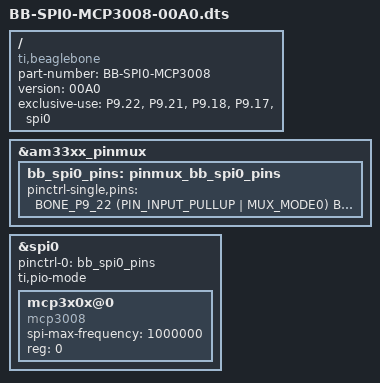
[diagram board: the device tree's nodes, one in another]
/*
 * Copyright (C) 2015 Robert Nelson <robertcnelson@gmail.com>
 *
 * This program is free software; you can redistribute it and/or modify
 * it under the terms of the GNU General Public License version 2 as
 * published by the Free Software Foundation.
 */
/dts-v1/;
/plugin/;

#include <dt-bindings/board/am335x-bbw-bbb-base.h>
#include <dt-bindings/pinctrl/am33xx.h>

/ {
	compatible = "ti,beaglebone", "ti,beaglebone-black", "ti,beaglebone-green";

	/* identification */
	part-number = "BB-SPI0-MCP3008";
	version = "00A0";

	/* state the resources this cape uses */
	exclusive-use =
		/* the pin header uses */
		"P9.22",	/* spi0_sclk, SPI0_SCLK */
		"P9.21",	/* spi0_d0, SPI0_MISO */
		"P9.18",	/* spi0_d1, SPI0_MOSI */
		"P9.17",	/* spi0_cs0, CS0 */
		/* the hardware ip uses */
		"spi0";

	fragment@0 {
		target = <&am33xx_pinmux>;
		__overlay__ {

			bb_spi0_pins: pinmux_bb_spi0_pins {
				pinctrl-single,pins = <
					BONE_P9_22 (PIN_INPUT_PULLUP | MUX_MODE0) /* spi0_sclk.spi0_sclk */
					BONE_P9_21 (PIN_INPUT_PULLUP | MUX_MODE0) /* spi0_d0.spi0_d0 */
					BONE_P9_18 (PIN_OUTPUT_PULLUP | MUX_MODE0) /* spi0_d0.spi0_d1 */
					BONE_P9_17 (PIN_OUTPUT_PULLUP | MUX_MODE0)  /* spi0_cs0.spi0_cs0 */
				>;
			};
		};
	};

	fragment@1 {
		target = <&spi0>;
		__overlay__ {
			#address-cells = <1>;
			#size-cells = <0>;

			pinctrl-names = "default";
			pinctrl-0 = <&bb_spi0_pins>;
			status = "okay";
			ti,pio-mode; /* disable dma when used as an overlay, dma gets stuck at 160 bits... */

			mcp3x0x@0 {
				spi-max-frequency = <1000000>;
				reg = <0>;
				compatible = "mcp3008";
			};
		};
	};
};
